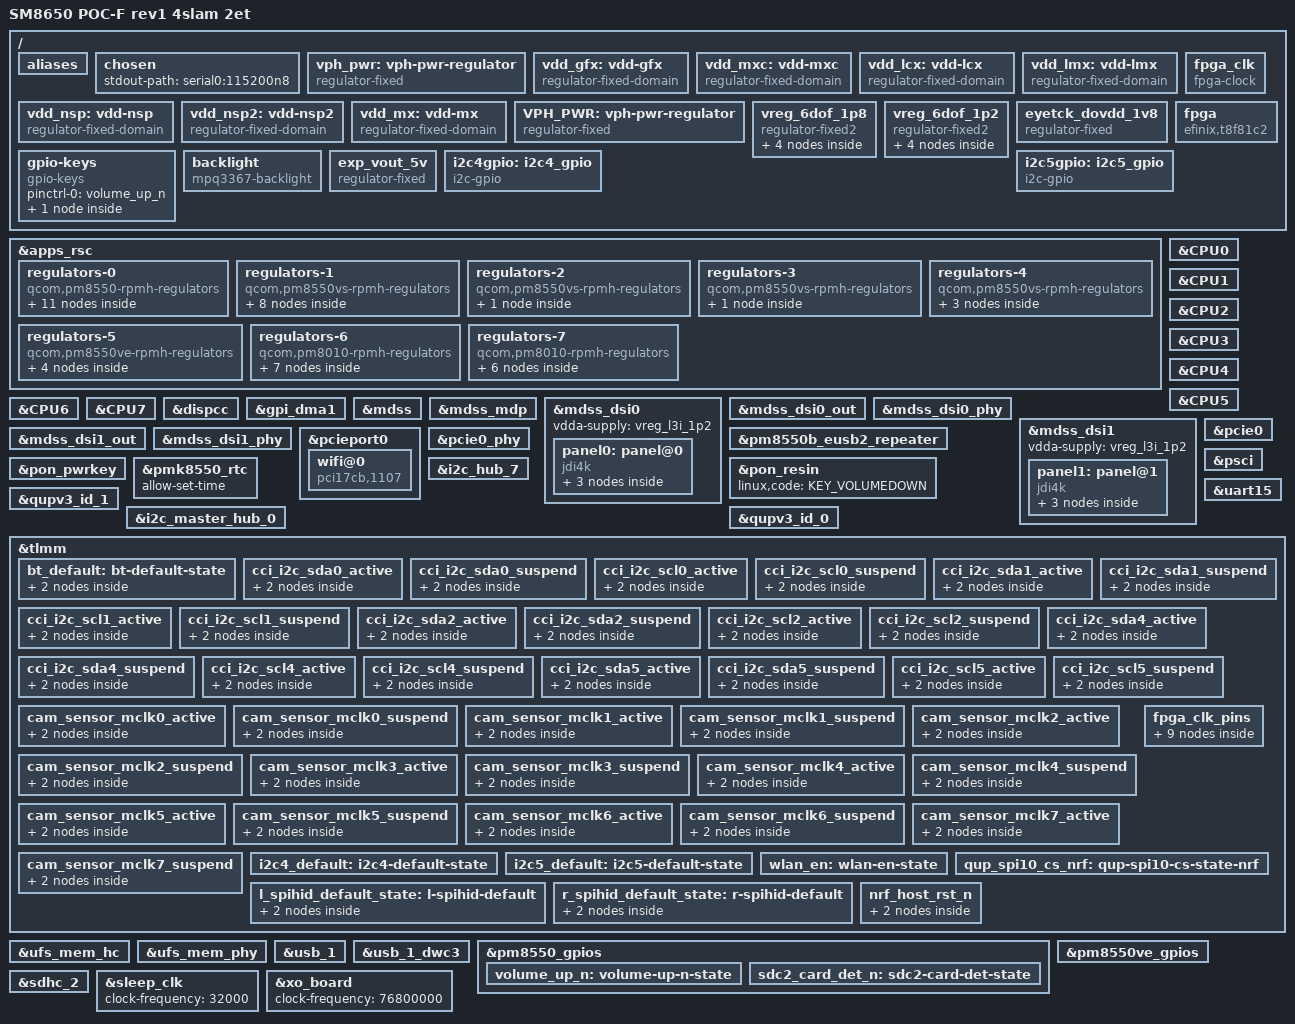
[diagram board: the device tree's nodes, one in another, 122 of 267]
/dts-v1/;

#include <dt-bindings/regulator/qcom,rpmh-regulator.h>
#include "sm8650.dtsi"

/delete-node/ &timer;

#include "pm8010.dtsi"
#include "pm8550.dtsi"
#include "pm8550b.dtsi"
#include "pm8550vs.dtsi"
#define PMK8550VE_SID 8
#include "pm8550ve.dtsi"
#include "pmk8550.dtsi"

#include <dt-bindings/regulator/qcom,rpmh-regulator.h>
#include <dt-bindings/usb/pd.h>
#include <dt-bindings/phy/phy.h>

#include <dt-bindings/input/input.h>


/ {
    model = "SM8650 POC-F rev1 4slam 2et";

	interrupt-parent = <&intc>;

	#address-cells = <2>;
	#size-cells = <2>;

	aliases {
		serial0 = &uart15;
		serial1 = &uart14;
	};

	chosen {
		stdout-path = "serial0:115200n8";
	};

	vph_pwr: vph-pwr-regulator {
		compatible = "regulator-fixed";

		regulator-name = "vph_pwr";
		regulator-min-microvolt = <3700000>;
		regulator-max-microvolt = <3700000>;

		regulator-always-on;
		regulator-boot-on;
	};

	vdd_gfx: vdd-gfx {
		compatible = "regulator-fixed-domain";
		power-domains = <&rpmhpd RPMHPD_GFX>;
		required-opps = <&rpmhpd_opp_nom>;
		regulator-name = "GFX";
		regulator-always-on;
	};

	vdd_mxc: vdd-mxc {
		compatible = "regulator-fixed-domain";
		power-domains = <&rpmhpd RPMHPD_MXC>;
		required-opps = <&rpmhpd_opp_nom>;
		regulator-name = "MXC";
		regulator-always-on;
	};

	vdd_lcx: vdd-lcx {
		compatible = "regulator-fixed-domain";
		power-domains = <&rpmhpd RPMHPD_LCX>;
		required-opps = <&rpmhpd_opp_nom>;
		regulator-name = "LCX";
		regulator-always-on;
	};

	vdd_lmx: vdd-lmx {
		compatible = "regulator-fixed-domain";
		power-domains = <&rpmhpd RPMHPD_LMX>;
		required-opps = <&rpmhpd_opp_nom>;
		regulator-name = "LMX";
		regulator-always-on;
	};

	vdd_nsp: vdd-nsp {
		compatible = "regulator-fixed-domain";
		power-domains = <&rpmhpd RPMHPD_NSP>;
		required-opps = <&rpmhpd_opp_nom>;
		regulator-name = "NSP";
		regulator-always-on;
	};

	vdd_nsp2: vdd-nsp2 {
		compatible = "regulator-fixed-domain";
		power-domains = <&rpmhpd RPMHPD_NSP2>;
		required-opps = <&rpmhpd_opp_nom>;
		regulator-name = "NSP2";
		regulator-always-on;
	};

	vdd_mx: vdd-mx {
		compatible = "regulator-fixed-domain";
		power-domains = <&rpmhpd RPMHPD_MX>;
		required-opps = <&rpmhpd_opp_nom>;
		regulator-name = "MX";
		regulator-always-on;
	};


	VPH_PWR: vph-pwr-regulator {
		compatible = "regulator-fixed";
		regulator-name = "VPH_PWR";
		regulator-min-microvolt = <3700000>;
		regulator-max-microvolt = <3700000>;

		regulator-always-on;
		regulator-boot-on;
	};

#if 0
	dummy_codec: dummy_codec {
		compatible = "linux,snd-soc-dummy";
		#sound-dai-cells = <0>;
	};

	sbu-mux {
		compatible = "gpio-sbu-mux";

		enable-gpios = <&tlmm 86 GPIO_ACTIVE_LOW>;
		select-gpios = <&tlmm 82 GPIO_ACTIVE_HIGH>;

		mode-switch;
		orientation-switch;

		port {
			sbu_mux_in: endpoint {
				remote-endpoint = <&tcpm_sbu_out>;
			};
		};

		// XXX: needs vreg_L05B_3P1, vreg_BOB2
	};
#endif

	vreg_6dof_1p8 {
		compatible = "regulator-fixed2";
		gpios = <&tlmm 36 GPIO_ACTIVE_HIGH>,
			<&tlmm 33 GPIO_ACTIVE_HIGH>;
		r-supply = <&vreg_l5m_1p8>;
		l-supply = <&vreg_l5n_1p8>;

		vreg_6dof_1p8_r: r0 {
			regulator-name = "vreg_6dof_1p8_r";
			regulator-min-microvolt = <1800000>;
			regulator-max-microvolt = <1800000>;
		};

		vreg_6dof_1p8_ur: r1 {
			regulator-name = "vreg_6dof_1p8_ur";
			regulator-min-microvolt = <1800000>;
			regulator-max-microvolt = <1800000>;
		};

		vreg_6dof_1p8_l: l0 {
			regulator-name = "vreg_6dof_1p8_l";
			regulator-min-microvolt = <1800000>;
			regulator-max-microvolt = <1800000>;
		};

		vreg_6dof_1p8_ul: l1 {
			regulator-name = "vreg_6dof_1p8_ul";
			regulator-min-microvolt = <1800000>;
			regulator-max-microvolt = <1800000>;
		};
	};

	vreg_6dof_1p2 {
		compatible = "regulator-fixed2";
		gpios = <&tlmm 37 GPIO_ACTIVE_HIGH>,
			<&tlmm 34 GPIO_ACTIVE_HIGH>;
		r-supply = <&vreg_l2m_1p2>;
		l-supply = <&vreg_l2n_1p2>;

		vreg_6dof_1p2_r: r0 {
			regulator-name = "vreg_6dof_1p2_r";
			regulator-min-microvolt = <1200000>;
			regulator-max-microvolt = <1200000>;
		};

		vreg_6dof_1p2_ur: r1 {
			regulator-name = "vreg_6dof_1p2_ur";
			regulator-min-microvolt = <1200000>;
			regulator-max-microvolt = <1200000>;
		};

		vreg_6dof_1p2_l: l0 {
			regulator-name = "vreg_6dof_1p2_l";
			regulator-min-microvolt = <1200000>;
			regulator-max-microvolt = <1200000>;
		};

		vreg_6dof_1p2_ul: l1 {
			regulator-name = "vreg_6dof_1p2_ul";
			regulator-min-microvolt = <1200000>;
			regulator-max-microvolt = <1200000>;
		};
	};

	eyetck_dovdd_1v8: eyetck_dovdd_1v8 {
		compatible = "regulator-fixed";
		regulator-name = "eyetck_dovdd_1v8";
		regulator-min-microvolt = <1800000>;
		regulator-max-microvolt = <1800000>;
		enable-active-high;
		gpio = <&tlmm 74 GPIO_ACTIVE_HIGH>;
		vin-supply = <&vreg_l5m_1p8>;
	};


	gpio-keys {
		compatible = "gpio-keys";

		pinctrl-0 = <&volume_up_n>;
		pinctrl-names = "default";

		key-volume-up {
			label = "Volume Up";
			linux,code = <KEY_VOLUMEUP>;
			gpios = <&pm8550_gpios 6 GPIO_ACTIVE_LOW>;
			debounce-interval = <15>;
			linux,can-disable;
			wakeup-source;
		};
	};

	backlight: backlight {
		compatible = "mpq3367-backlight";
		preboost-gpio = <&tlmm 41 GPIO_ACTIVE_HIGH>;
		en-gpios = <&pm8550_gpios 1 GPIO_ACTIVE_HIGH>,
			   <&pm8550_gpios 2 GPIO_ACTIVE_HIGH>;
		bias-gpios = <&pm8550_gpios 4 GPIO_ACTIVE_HIGH>,
			     <&pm8550_gpios 9 GPIO_ACTIVE_HIGH>;
		i2c-adapter = <&i2c4gpio &i2c5gpio>;
	};

	fpga_clk: fpga_clk {
		compatible = "fpga-clock";
		#clock-cells = <0>;
		clock-output-names = "fpga_clk";
		status = "okay";

		pinctrl-0 = <&fpga_clk_default>;
		pinctrl-names = "default";

		clocks = <&gcc GCC_GP3_CLK>;
		clock-frequency = <33333333>;
		clock-names = "pinclk";
	};

	fpga: fpga {
		compatible = "efinix,t8f81c2";

		clocks = <&fpga_clk>;
		clock-names = "fpga_clk";
		v1v1-supply = <&vreg_l2g_1p1>;
		pwren-gpio = <&tlmm 75 GPIO_ACTIVE_HIGH>;
	};

	exp_vout_5v: exp_vout_5v {
		compatible = "regulator-fixed";
		regulator-name = "exp_vout_5v";
		regulator-min-microvolt = <5000000>;
		regulator-max-microvolt = <5000000>;
		gpio = <&pm8550vs_g_gpios 6 GPIO_ACTIVE_HIGH>;
		enable-active-high;
		vin-supply = <&vph_pwr>;
		regulator-always-on;
	};

	i2c4gpio: i2c4_gpio {
		compatible = "i2c-gpio";
		sda-gpios = <&tlmm 48 (GPIO_ACTIVE_HIGH|GPIO_OPEN_DRAIN)>;
		scl-gpios = <&tlmm 49 (GPIO_ACTIVE_HIGH|GPIO_OPEN_DRAIN)>;

		pinctrl-0 = <&i2c4_default>;
		pinctrl-names = "default";

		#address-cells = <1>;
		#size-cells = <0>;
	};

	i2c5gpio: i2c5_gpio {
		compatible = "i2c-gpio";
		sda-gpios = <&tlmm 52 (GPIO_ACTIVE_HIGH|GPIO_OPEN_DRAIN)>;
		scl-gpios = <&tlmm 53 (GPIO_ACTIVE_HIGH|GPIO_OPEN_DRAIN)>;

		pinctrl-0 = <&i2c5_default>;
		pinctrl-names = "default";

		#address-cells = <1>;
		#size-cells = <0>;
	};
};

#if 0
&pmk8550_vadc {
	// NOTE TODO REVISIT - There is some chance to lower interrupt usage slightly if these are converted to thermal zones and qcom,adc-tm-type is set appropriately..

	// NOTE Setting qcom,adc-tm-type errors out driver and blocks all channels with obscure error. Need Thermal Zone setup to match.
	pmk8550_xo_therm {
		reg = <PMK8550_ADC5_GEN3_AMUX_THM1_XO_THERM_100K_PU>;
		label = "pmk8550_xo_therm";
		qcom,ratiometric;
		qcom,hw-settle-time = <200>;
		qcom,pre-scaling = <1 1>;
	};


	/* External PM8550 Thermistors */
	// 200 us measured on POC-F Boards as required time to reach stability.
	pcba_at_fan_exhaust {
		// Quiet Therm RT0502
		reg = <PM8550_ADC5_GEN3_AMUX_THM1_100K_PU>;
		label = "pcba_at_fan_exhaust";
		qcom,hw-settle-time = <200>;
		qcom,ratiometric;
	};

	pcba_at_40pin_connector {
		// SDM SKIN Therm RT507
		reg = <PM8550_ADC5_GEN3_AMUX_THM2_100K_PU>;
		label = "pcba_at_40pin_connector";
		qcom,hw-settle-time = <200>;
		qcom,ratiometric;
	};

	pcba_at_wifi {
		// WLAN Therm RT0503
		reg = <PM8550_ADC5_GEN3_AMUX_THM3_100K_PU>;
		label = "pcba_at_wifi";
		qcom,hw-settle-time = <200>;
		qcom,ratiometric;
	};

	pcba_at_flash {
		// ADC_1 Therm RT506
		reg = <PM8550_ADC5_GEN3_AMUX_THM4_100K_PU>;
		label = "pcba_at_flash";
		qcom,hw-settle-time = <200>;
		qcom,ratiometric;
	};

	pcba_at_nrf {
		// ADC_2 Therm RT505
		reg = <PM8550_ADC5_GEN3_AMUX_THM5_100K_PU>;
		label = "pcba_at_nrf";
		qcom,hw-settle-time = <200>;
		qcom,ratiometric;
	};


	/* External PM8550B Thermistors */
	pcba_at_heat_sink_fins {
		reg = <PM8550B_ADC5_GEN3_AMUX_THM4_USB_THERM_100K_PU>;
		label = "pcba_at_heat_sink_fins";
		qcom,hw-settle-time = <200>;
		qcom,ratiometric;
	};
};
#endif

// Different scaling for 2S
// TGOYEN - I am not fully sure how this comes about.
// It definitely doesn't match the values expected by the driver.
// I found documentation mapping 28,848 counts = 12 Amps.
// However, this is wrong since we use 4.22k for ICHG_FB which makes 60 mA steps
// So the correct mapping is 28,848 * 50 / 60 = 24,040 counts = 12 Amps
// Mapping is then 12,000,000 / 24,040
// NOTE This scaling has to be added to qcom-vadc-common.c as well
/*
&pm8550b_ichg_fb {
	qcom,pre-scaling = <24040 12000000>;
};
*/

&apps_rsc {
	/delete-property/ power-domains;

	regulators-0 {
		compatible = "qcom,pm8550-rpmh-regulators";

		vdd-bob1-supply = <&vph_pwr>;
		vdd-bob2-supply = <&vph_pwr>;
		vdd-l1-l4-l10-supply = <&vreg_s6c_1p8>;
		vdd-l2-l13-l14-supply = <&vreg_bob1>;
		vdd-l3-supply = <&vreg_s1c_1p2>;
		vdd-l5-l16-supply = <&vreg_bob1>;
		vdd-l8-l9-supply = <&vreg_bob1>;
		vdd-l12-supply = <&vreg_s6c_1p8>;
		vdd-l15-supply = <&vreg_s6c_1p8>;
		vdd-l17-supply = <&vreg_bob2>;

		qcom,pmic-id = "b";

		vreg_bob1: bob1 {
			regulator-name = "vreg_bob1";
			regulator-min-microvolt = <3296000>; // note: min is 3008000, init is 3296000
			regulator-max-microvolt = <3960000>;
			regulator-initial-mode = <RPMH_REGULATOR_MODE_HPM>;
		};

		vreg_bob2: bob2 {
			regulator-name = "vreg_bob2";
			regulator-min-microvolt = <2720000>; // note: min is 2704000, init is 2720000
			regulator-max-microvolt = <3008000>;

			regulator-initial-mode = <RPMH_REGULATOR_MODE_HPM>;

			regulator-always-on; // XXX USB HS, SBU MUX
		};

		vdd_sensor_1p8: vreg_l1b_1p8: ldo1 {
			regulator-name = "vreg_l1b_1p8";
			regulator-min-microvolt = <1800000>;
			regulator-max-microvolt = <1800000>;
			regulator-initial-mode = <RPMH_REGULATOR_MODE_HPM>;

			regulator-always-on; // XXX sensors
		};

		vdd_sensor_3p0: vreg_l2b_3p0: ldo2 {
			regulator-name = "vreg_l2b_3p0";
			regulator-min-microvolt = <3008000>;
			regulator-max-microvolt = <3008000>;
			regulator-initial-mode = <RPMH_REGULATOR_MODE_HPM>;

			regulator-always-on; // XXX sensors
		};

		vreg_l5b_3p1: ldo5 {
			regulator-name = "vreg_l5b_3p1";
			regulator-min-microvolt = <3104000>;
			regulator-max-microvolt = <3104000>;
			regulator-initial-mode = <RPMH_REGULATOR_MODE_HPM>;
			regulator-allow-set-load;
			regulator-allowed-modes = <RPMH_REGULATOR_MODE_LPM
						   RPMH_REGULATOR_MODE_HPM>;
			regulator-always-on; // XXX SBU MUX
		};

		vreg_l8b_1p8: ldo8 {
			regulator-name = "vreg_l8b_1p8";
			regulator-min-microvolt = <1800000>;
			regulator-max-microvolt = <1800000>;
			regulator-initial-mode = <RPMH_REGULATOR_MODE_HPM>;
			regulator-allow-set-load;
			regulator-allowed-modes = <RPMH_REGULATOR_MODE_LPM
						   RPMH_REGULATOR_MODE_HPM>;
		};

		vreg_l9b_2p9: ldo9 {
			regulator-name = "vreg_l9b_2p9";
			regulator-min-microvolt = <2960000>;
			regulator-max-microvolt = <2960000>;
			regulator-initial-mode = <RPMH_REGULATOR_MODE_HPM>;
			regulator-allow-set-load;
			regulator-allowed-modes = <RPMH_REGULATOR_MODE_LPM
						   RPMH_REGULATOR_MODE_HPM>;
		};

		vreg_l10b_1p8: ldo10 {
			regulator-name = "vreg_l10b_1p8";
			regulator-min-microvolt = <1800000>;
			regulator-max-microvolt = <1800000>;
			regulator-initial-mode = <RPMH_REGULATOR_MODE_HPM>;

			regulator-always-on; // XXX DMIC
		};

		vreg_l12b_1p8: ldo12 {
			regulator-name = "vreg_l12b_1p8";
			regulator-min-microvolt = <1800000>;
			regulator-max-microvolt = <1800000>;
			regulator-initial-mode = <RPMH_REGULATOR_MODE_HPM>;
			regulator-allow-set-load;
			regulator-allowed-modes = <RPMH_REGULATOR_MODE_LPM
						   RPMH_REGULATOR_MODE_HPM>;
		};

		vreg_l15b_1p8: ldo15 {
			regulator-name = "vreg_l15b_1p8";
			regulator-min-microvolt = <1800000>;
			regulator-max-microvolt = <1800000>;
			regulator-initial-mode = <RPMH_REGULATOR_MODE_HPM>;
			regulator-allow-set-load;
			regulator-allowed-modes = <RPMH_REGULATOR_MODE_LPM
						   RPMH_REGULATOR_MODE_HPM>;
			regulator-always-on; // XXX: 1.8V pull ups
		};

		vreg_l17b_2p5: ldo17 {
			regulator-name = "vreg_l17b_2p5";
			regulator-min-microvolt = <2504000>;
			regulator-max-microvolt = <2504000>;
			regulator-initial-mode = <RPMH_REGULATOR_MODE_HPM>;
			regulator-allow-set-load;
			regulator-allowed-modes = <RPMH_REGULATOR_MODE_LPM
						   RPMH_REGULATOR_MODE_HPM>;
		};
	};

	regulators-1 {
		compatible = "qcom,pm8550vs-rpmh-regulators";

		vdd-l1-supply = <&vreg_s1c_1p2>;
		vdd-l3-supply = <&vreg_s1c_1p2>;
		vdd-s1-supply = <&vph_pwr>;
		vdd-s2-supply = <&vph_pwr>;
		vdd-s3-supply = <&vph_pwr>;
		vdd-s4-supply = <&vph_pwr>;
		vdd-s5-supply = <&vph_pwr>;
		vdd-s6-supply = <&vph_pwr>;

		qcom,pmic-id = "c";

		vreg_s1c_1p2: smps1 {
			regulator-name = "vreg_s1c_1p2";
			regulator-min-microvolt = <1224000>;
			regulator-max-microvolt = <1348000>;
			// init 1256000
			regulator-initial-mode = <RPMH_REGULATOR_MODE_HPM>;

			regulator-always-on; // USB, UFS?
		};

		vreg_s2c_0p8: smps2 {
			regulator-name = "vreg_s2c_0p8";
			regulator-min-microvolt = <500000>;
			regulator-max-microvolt = <1036000>;
			// init 852000
			regulator-initial-mode = <RPMH_REGULATOR_MODE_HPM>;
		};

		vreg_s3c_0p9: smps3 {
			regulator-name = "vreg_s3c_0p9";
			regulator-min-microvolt = <904000>;
			regulator-max-microvolt = <1064000>;
			// init 976000
			regulator-initial-mode = <RPMH_REGULATOR_MODE_HPM>;
		};

		vreg_s4c_1p2: smps4 {
			regulator-name = "vreg_s4c_1p2";
			regulator-min-microvolt = <1200000>;
			regulator-max-microvolt = <1280000>;
			// init 1224000
			regulator-initial-mode = <RPMH_REGULATOR_MODE_HPM>;
		};

		vreg_s5c_0p7: smps5 {
			regulator-name = "vreg_s5c_0p7";
			regulator-min-microvolt = <300000>;
			regulator-max-microvolt = <900000>;
			// init 752000
			regulator-initial-mode = <RPMH_REGULATOR_MODE_HPM>;
		};

		vreg_s6c_1p8: smps6 {
			regulator-name = "vreg_s6c_1p8";
			regulator-min-microvolt = <1856000>;
			regulator-max-microvolt = <2000000>;
			// init 1856000
			regulator-initial-mode = <RPMH_REGULATOR_MODE_HPM>;
		};

		vreg_l1c_1p2: ldo1 {
			regulator-name = "vreg_l1c_1p2";
			regulator-min-microvolt = <1200000>; // note: min 1100000
			regulator-max-microvolt = <1200000>;
			regulator-initial-mode = <RPMH_REGULATOR_MODE_HPM>;
			regulator-allow-set-load;
			regulator-allowed-modes = <RPMH_REGULATOR_MODE_LPM
						   RPMH_REGULATOR_MODE_HPM>;
		};

		vreg_l3c_1p2: ldo3 {
			regulator-name = "vreg_l3c_1p2";
			regulator-min-microvolt = <1200000>;
			regulator-max-microvolt = <1200000>;
			regulator-initial-mode = <RPMH_REGULATOR_MODE_HPM>;
			regulator-allow-set-load;
			regulator-allowed-modes = <RPMH_REGULATOR_MODE_LPM
						   RPMH_REGULATOR_MODE_HPM>;
			regulator-always-on; // XXX: 1.2V pull ups
		};
	};

	regulators-2 {
		compatible = "qcom,pm8550vs-rpmh-regulators";
		qcom,pmic-id = "d";

		vdd-l1-supply = <&vreg_s3c_0p9>;

		vreg_l1d_0p9: ldo1 {
			regulator-name = "vreg_l1d_0p9";
			regulator-min-microvolt = <912000>; // note: min 880000
			regulator-max-microvolt = <920000>;
			regulator-initial-mode = <RPMH_REGULATOR_MODE_HPM>;
			regulator-allow-set-load;
			regulator-allowed-modes = <RPMH_REGULATOR_MODE_LPM
						   RPMH_REGULATOR_MODE_HPM>;
		};
	};

	regulators-3 {
		compatible = "qcom,pm8550vs-rpmh-regulators";
		qcom,pmic-id = "e";

		vdd-l3-supply = <&vreg_s3c_0p9>;

		vreg_l3e_0p9: ldo3 {
			regulator-name = "vreg_l3e_0p9";
			regulator-min-microvolt = <880000>;
			regulator-max-microvolt = <920000>;
			regulator-initial-mode = <RPMH_REGULATOR_MODE_HPM>;
			regulator-allow-set-load;
			regulator-allowed-modes = <RPMH_REGULATOR_MODE_LPM
						   RPMH_REGULATOR_MODE_HPM>;
		};
	};

	regulators-4 {
		compatible = "qcom,pm8550vs-rpmh-regulators";
		qcom,pmic-id = "g";

		vdd-l1-supply = <&vreg_s3c_0p9>;
		vdd-l2-supply = <&vreg_s1c_1p2>;
		vdd-l3-supply = <&vreg_s3c_0p9>;

		vreg_l1g_0p9: ldo1 {
			regulator-name = "vreg_l1g_0p9";
			regulator-min-microvolt = <912000>;
			regulator-max-microvolt = <920000>;
			regulator-initial-mode = <RPMH_REGULATOR_MODE_HPM>;
			// QLINK ?
		};

		vreg_l2g_1p1: ldo2 {
			regulator-name = "vreg_l2g_1p1";
			regulator-min-microvolt = <1104000>;
			regulator-max-microvolt = <1104000>;
			regulator-initial-mode = <RPMH_REGULATOR_MODE_HPM>;
		};

		vreg_l3g_0p91: ldo3 {
			regulator-name = "vreg_l3g_0p91";
			regulator-min-microvolt = <880000>;
			regulator-max-microvolt = <912000>;
			regulator-initial-mode = <RPMH_REGULATOR_MODE_HPM>;
		};
	};

	regulators-5 {
		compatible = "qcom,pm8550ve-rpmh-regulators";
		qcom,pmic-id = "i";

		vdd-l1-supply = <&vreg_s3c_0p9>;
		vdd-l2-supply = <&vreg_s3c_0p9>;
		vdd-l3-supply = <&vreg_s1c_1p2>;
		vdd-s4-supply = <&vph_pwr>;

		vreg_s4i_0p85: smps4 {
			regulator-name = "vreg_s4i_0p85";
			regulator-min-microvolt = <852000>;
			regulator-max-microvolt = <1004000>;
			// init 852000
			regulator-initial-mode = <RPMH_REGULATOR_MODE_HPM>;
		};

		vreg_l1i_0p88: ldo1 {
			regulator-name = "vreg_l1i_0p88";
			regulator-min-microvolt = <880000>;
			regulator-max-microvolt = <912000>;
			regulator-initial-mode = <RPMH_REGULATOR_MODE_HPM>;
			regulator-allow-set-load;
			regulator-allowed-modes = <RPMH_REGULATOR_MODE_LPM
						   RPMH_REGULATOR_MODE_HPM>;
		};

		vreg_l2i_0p88: ldo2 {
			regulator-name = "vreg_l2i_0p88";
			regulator-min-microvolt = <880000>;
			regulator-max-microvolt = <912000>;
			regulator-initial-mode = <RPMH_REGULATOR_MODE_HPM>;
			regulator-allow-set-load;
			regulator-allowed-modes = <RPMH_REGULATOR_MODE_LPM
						   RPMH_REGULATOR_MODE_HPM>;

			regulator-always-on; // CSI PHY
		};

		vreg_l3i_1p2: ldo3 {
			regulator-name = "vreg_l3i_1p2";
			regulator-min-microvolt = <1200000>;
			regulator-max-microvolt = <1200000>;
			regulator-initial-mode = <RPMH_REGULATOR_MODE_HPM>;

			regulator-always-on; // CSI PHY
		};
	};

	regulators-6 {
		compatible = "qcom,pm8010-rpmh-regulators";
		qcom,pmic-id = "m";

		vdd-l1-l2-supply = <&vreg_s1c_1p2>;
		vdd-l3-l4-supply = <&vreg_bob2>;
		vdd-l5-supply = <&vreg_s6c_1p8>;
		vdd-l6-supply = <&vreg_bob1>;
		vdd-l7-supply = <&vreg_bob1>;

		vreg_l1m_1p1: ldo1 {
			regulator-name = "vreg_l1m_1p1";
			regulator-min-microvolt = <1104000>;
			regulator-max-microvolt = <1104000>;
			regulator-initial-mode = <RPMH_REGULATOR_MODE_HPM>;
			regulator-allow-set-load;
			regulator-allowed-modes = <RPMH_REGULATOR_MODE_LPM
						   RPMH_REGULATOR_MODE_HPM>;
		};

		vreg_l2m_1p2: ldo2 {
			regulator-name = "vreg_l2m_1p2";
			regulator-min-microvolt = <1200000>;
			regulator-max-microvolt = <1200000>;
			regulator-initial-mode = <RPMH_REGULATOR_MODE_HPM>;
			regulator-allow-set-load;
			regulator-allowed-modes = <RPMH_REGULATOR_MODE_LPM
						   RPMH_REGULATOR_MODE_HPM>;
		};

		vreg_6dof_2p8_r: vreg_l3m_2p8: ldo3 {
			regulator-name = "vreg_l3m_2p8";
			regulator-min-microvolt = <2800000>;
			regulator-max-microvolt = <2800000>;
			regulator-initial-mode = <RPMH_REGULATOR_MODE_HPM>;
		};

		vreg_6dof_2p8_ur: vreg_l4m_2p8: ldo4 {
			regulator-name = "vreg_l4m_2p8";
			regulator-min-microvolt = <2800000>;
			regulator-max-microvolt = <2800000>;
			regulator-initial-mode = <RPMH_REGULATOR_MODE_HPM>;
		};

		vreg_l5m_1p8: ldo5 {
			regulator-name = "vreg_l5m_1p8";
			regulator-min-microvolt = <1800000>;
			regulator-max-microvolt = <1800000>;
			regulator-initial-mode = <RPMH_REGULATOR_MODE_HPM>;
		};

		vreg_l6m_2p8: ldo6 {
			regulator-name = "vreg_l6m_2p8";
			regulator-min-microvolt = <2800000>;
			regulator-max-microvolt = <2800000>;
			regulator-initial-mode = <RPMH_REGULATOR_MODE_HPM>;
		};

		vreg_l7m_3p3: ldo7 {
			regulator-name = "vreg_l7m_3p3";
			regulator-min-microvolt = <3304000>;
			regulator-max-microvolt = <3304000>;
			regulator-initial-mode = <RPMH_REGULATOR_MODE_HPM>;

			regulator-always-on;
		};
	};

	regulators-7 {
		compatible = "qcom,pm8010-rpmh-regulators";
		qcom,pmic-id = "n";

		vdd-l1-l2-supply = <&vreg_s1c_1p2>;
		vdd-l3-l4-supply = <&vreg_bob2>;
		vdd-l5-supply = <&vreg_s6c_1p8>;
		vdd-l6-supply = <&vreg_bob1>;

		vreg_l1n_1p1: ldo1 {
			regulator-name = "vreg_l1n_1p1";
			regulator-min-microvolt = <1104000>;
			regulator-max-microvolt = <1104000>;
			regulator-initial-mode = <RPMH_REGULATOR_MODE_HPM>;
			regulator-allow-set-load;
			regulator-allowed-modes = <RPMH_REGULATOR_MODE_LPM
						   RPMH_REGULATOR_MODE_HPM>;
		};

		vreg_l2n_1p2: ldo2 {
			regulator-name = "vreg_l2n_1p2";
			regulator-min-microvolt = <1200000>;
			regulator-max-microvolt = <1200000>;
			regulator-initial-mode = <RPMH_REGULATOR_MODE_HPM>;
			regulator-allow-set-load;
			regulator-allowed-modes = <RPMH_REGULATOR_MODE_LPM
						   RPMH_REGULATOR_MODE_HPM>;
		};

		vreg_6dof_2p8_l: vreg_l3n_2p8: ldo3 {
			regulator-name = "vreg_l3n_2p8";
			regulator-min-microvolt = <2800000>;
			regulator-max-microvolt = <2800000>;
			regulator-initial-mode = <RPMH_REGULATOR_MODE_HPM>;
		};

		vreg_6dof_2p8_ul: vreg_l4n_2p8: ldo4 {
			regulator-name = "vreg_l4n_2p8";
			regulator-min-microvolt = <2800000>;
			regulator-max-microvolt = <2800000>;
			regulator-initial-mode = <RPMH_REGULATOR_MODE_HPM>;
		};

		vreg_l5n_1p8: ldo5 {
			regulator-name = "vreg_l5n_1p8";
			regulator-min-microvolt = <1800000>;
			regulator-max-microvolt = <1800000>;
			regulator-initial-mode = <RPMH_REGULATOR_MODE_HPM>;
		};

		vreg_l6n_2p8: ldo6 {
			regulator-name = "vreg_l6n_2p8";
			regulator-min-microvolt = <2800000>;
			regulator-max-microvolt = <2800000>;
			regulator-initial-mode = <RPMH_REGULATOR_MODE_HPM>;
		};
	};
};

&CPU0 {
	/delete-property/ power-domains;
};

&CPU1 {
	/delete-property/ power-domains;
};

&CPU2 {
	/delete-property/ power-domains;
};

&CPU3 {
	/delete-property/ power-domains;
};

&CPU4 {
	/delete-property/ power-domains;
};

&CPU5 {
	/delete-property/ power-domains;
};

&CPU6 {
	/delete-property/ power-domains;
};

&CPU7 {
	/delete-property/ power-domains;
};

&dispcc {
	status = "okay";
};

&gpi_dma1 {
	status = "okay";
};

&mdss {
	status = "okay";
};

&mdss_mdp {
	status = "okay";
};

&mdss_dsi0 {
	vdda-supply = <&vreg_l3i_1p2>;
	status = "okay";

/*
	qcom,dual-dsi-mode;
	qcom,master-dsi;
*/


	panel0: panel@0 {
		reg = <0>;
		compatible = "jdi4k";
		id = <0>;

		reset-gpios =<&pm8550_gpios 3 GPIO_ACTIVE_HIGH>;
		reset2-gpios =<&pm8550_gpios 11 GPIO_ACTIVE_HIGH>;
		enp-gpios = <&tlmm 32 GPIO_ACTIVE_HIGH>;
		// XXX or tlmm 121 boost?

		wled1-supply = <&backlight>;
		vdda-supply = <&vreg_l12b_1p8>;

		//pinctrl-names = "default";
		//pinctrl-0 = <&sde_dsi_active>;

		ports {
			#address-cells = <1>;
			#size-cells = <0>;
			port@0 {
				reg = <0>;
				panel0_in: endpoint {
					remote-endpoint = <&mdss_dsi0_out>;
				};
			};

/*
			port@1 {
				reg = <1>;
				panel1_in: endpoint {
					remote-endpoint = <&mdss_dsi1_out>;
				};
			};
*/
		};
	};
};

&mdss_dsi0_out {
	remote-endpoint = <&panel0_in>;
	data-lanes = <0 1 2>;
};

&mdss_dsi0_phy {
	vdds-supply = <&vreg_l1i_0p88>;
	status = "okay";
	phy-type = <PHY_TYPE_CPHY>;
};

#if 1
&mdss_dsi1 {
	vdda-supply = <&vreg_l3i_1p2>;
	status = "okay";

#if 0
	qcom,dual-dsi-mode;

	assigned-clocks = <&dispcc DISP_CC_MDSS_BYTE1_CLK_SRC>, <&dispcc DISP_CC_MDSS_PCLK1_CLK_SRC>;
	assigned-clock-parents = <&mdss_dsi0_phy 0>, <&mdss_dsi0_phy 1>;
#endif
	panel1: panel@1 {
		reg = <0>;
		compatible = "jdi4k";
		id = <1>;

		//pinctrl-names = "default";
		//pinctrl-0 = <&sde_dsi_active>;

		ports {
			#address-cells = <1>;
			#size-cells = <0>;
			port@1 {
				reg = <1>;
				panel1_in: endpoint {
					remote-endpoint = <&mdss_dsi1_out>;
				};
			};
		};
	};
};

&mdss_dsi1_out {
	remote-endpoint = <&panel1_in>;
	data-lanes = <0 1 2>;
};

&mdss_dsi1_phy {
	vdds-supply = <&vreg_l1i_0p88>;
	status = "okay";
	phy-type = <PHY_TYPE_CPHY>;
};
#endif

#if 0
&msm_dp {
	status = "okay";
	mode-switch;
	svid = /bits/ 16 <0xff01>;

	port {
		dp_mode: endpoint@0 {
			remote-endpoint = <&dp_mode_out>;
		};
	};
};
#endif

&pcie0 {
	wake-gpios = <&tlmm 96 GPIO_ACTIVE_HIGH>;
	perst-gpios = <&tlmm 94 GPIO_ACTIVE_LOW>;

	pinctrl-names = "default";
	pinctrl-0 = <&pcie0_default_state>;

	status = "okay";
};

&pcieport0 {
	wifi@0 {
		compatible = "pci17cb,1107";
		reg = <0x10000 0x0 0x0 0x0 0x0>;

		pinctrl-names = "default";
		pinctrl-0 = <&wlan_en>;

		enable-gpios = <&tlmm 16 GPIO_ACTIVE_HIGH>;

		vddio12-supply = <&vreg_l3c_1p2>;
		vddio-supply = <&vreg_l15b_1p8>;
		vdd-supply = <&vreg_s4i_0p85>;
		vddaon-supply = <&vreg_s2c_0p8>;
		vdddig-supply = <&vreg_s3c_0p9>;
		vddrfa1-supply = <&vreg_s6c_1p8>;
		vddrfa2-supply = <&vreg_s1c_1p2>;

		clocks = <&rpmhcc RPMH_RF_CLK1>;
	};
};

&pcie0_phy {
	vdda-phy-supply = <&vreg_l1i_0p88>;
	vdda-pll-supply = <&vreg_l3i_1p2>;

	status = "okay";
};

&pm8550b_eusb2_repeater {
	vdd18-supply = <&vreg_l15b_1p8>;
	vdd3-supply = <&vreg_l5b_3p1>;
};

#if 0
&pm8550b_vbus {
	status = "okay";
};

&pm8550b_typec {
	status = "okay";

	vdd-pdphy-supply = <&vreg_l5b_3p1>;

	connector {
		power-role = "dual";
		data-role = "dual";
		try-power-role = "sink";
		source-pdos = <PDO_FIXED(5000, 1500, PDO_FIXED_DUAL_ROLE | PDO_FIXED_DATA_SWAP |
		  PDO_FIXED_USB_COMM)>;
        sink-pdos = <PDO_FIXED(5000, 3000, PDO_FIXED_DUAL_ROLE | PDO_FIXED_DATA_SWAP | PDO_FIXED_USB_COMM)>,
                    <PDO_FIXED(9000, 3000, PDO_FIXED_DUAL_ROLE | PDO_FIXED_DATA_SWAP | PDO_FIXED_USB_COMM)>;
		op-sink-microwatt = <15000000>;

		ports {
			#address-cells = <1>;
			#size-cells = <0>;

			port@0 {
				reg = <0>;

				pm8550b_role_switch_out: endpoint {
					remote-endpoint = <&usb_1_dwc3_role_switch_in>;
				};
			};

			port@1 {
				reg = <1>;

				tcpm_sbu_out: endpoint {
					remote-endpoint = <&sbu_mux_in>;
				};
			};

			port@2 {
				reg = <2>;

				dp_mode_out: endpoint {
					remote-endpoint = <&dp_mode>;
				};
			};

#if 0
			port@1 {
				reg = <1>;

				pm8550b_typec_mux_out: endpoint {
					remote-endpoint = <&usb_1_qmpphy_typec_mux_in>;
				};
			};
#endif
		};
	};

};
#endif

&pon_pwrkey {
	status = "okay";
};

&pon_resin {
	linux,code = <KEY_VOLUMEDOWN>;
	status = "okay";
};

&pmk8550_rtc {
	allow-set-time;
};

&psci {
	/delete-node/ power-domain-cpu0;
	/delete-node/ power-domain-cpu1;
	/delete-node/ power-domain-cpu2;
	/delete-node/ power-domain-cpu3;
	/delete-node/ power-domain-cpu4;
	/delete-node/ power-domain-cpu5;
	/delete-node/ power-domain-cpu6;
	/delete-node/ power-domain-cpu7;
	/delete-node/ power-domain-cluster;
};

&qupv3_id_1 {
	status = "okay";
};


#if 0
&i2c4 {
	status = "okay";

#if 0
    /* FAN_I2C */
	slg4ax46073v@8 {
		compatible = "silego,slg4ax46073v";
		reg = <0x08>;
		#address-cells = <1>;
		#size-cells = <0>;

		//vdd-fan-1-supply = <&VBATT_2S>; not modeled in dts
		fan-alert-gpios = <&tlmm 174 GPIO_ACTIVE_HIGH>;
		en-gpio = <&tlmm 138 GPIO_ACTIVE_HIGH>;
		bp-gpio = <&tlmm 139 GPIO_ACTIVE_HIGH>;

		status = "ok";
	};

	/* 3D Hall Sensor I2C */
	als31300@6c {
		compatible = "allegro,als31300";
		reg = <0x6c>;
		#address-cells = <1>;
		#size-cells = <0>;

		//vdd-hall-supply = <&VDD_SENSOR_3V0>; // Always On
		//hall-alert-gpios = <&tlmm 65 GPIO_ACTIVE_LOW>; // Not Used

		status = "ok";
	};
#endif
};

&i2c5 {
	status = "okay";
};
#endif

// Master Hub required for Hub 7 and 8
&i2c_master_hub_0 {
	status = "okay";
};

// Custom Connector I2C
&i2c_hub_7 {
	status = "okay";
};

// Prox Sensor I2C
#if 0
&i2c_hub_8 {
	status = "okay";

	light-sensor@60 {
		compatible = "vishay,vcnl4040";
		reg = <0x60>;
		proximity-near-level = <220>;
		// interrupts-extended = <&tlmm 31 IRQ_TYPE_EDGE_FALLING>;
		// driver lacks support for regulators, l8c and l11c set to always on

		vin0-supply = <&vdd_sensor_3p0>;
		vin1-supply = <&vreg_l15b_1p8>; 

		status = "okay";
	};
};
#endif

&qupv3_id_0 {
	status = "okay";
};

&qupv3_id_1 {
	status = "okay";
};

#if 0
&uart14 {
	status = "okay";

	bluetooth {
		compatible = "qcom,wcn7850-bt";

		// XXX check these
		vddio-supply = <&vreg_l15b_1p8>;
		vddaon-supply = <&vreg_s3c_0p9>;
		vdddig-supply = <&vreg_s2c_0p8>;
		vddrfa0p8-supply = <&vreg_s3c_0p9>;
		vddrfa1p2-supply = <&vreg_s1c_1p2>;
		vddrfa1p9-supply = <&vreg_s6c_1p8>;

		max-speed = <3200000>;

		enable-gpios = <&tlmm 17 GPIO_ACTIVE_HIGH>;
		swctrl-gpios = <&tlmm 18 GPIO_ACTIVE_HIGH>;

		pinctrl-0 = <&bt_default>;
		pinctrl-names = "default";

		// XXX needs to be different for each device
		local-bd-address = [ 55 44 33 22 11 00 ];
	};
};
#endif

&uart15 {
	status = "okay";
};

#if 0
&qupv3_ssc {
	status = "okay";
};

&ssc_i2c9 {
	status = "okay";
};
#endif

&tlmm {
	bt_default: bt-default-state {
		bt-en-pins {
			pins = "gpio17";
			function = "gpio";
			drive-strength = <16>;
			bias-disable;
		};

		sw-ctrl-pins {
			pins = "gpio18";
			function = "gpio";
			bias-pull-down;
		};
	};

	cci_i2c_sda0_active: cci_i2c_sda0_active {
		mux {
			/* CLK, DATA */
			pins = "gpio113";
			function = "cci_i2c_sda";
		};

		config {
			pins = "gpio113";
			bias-pull-up; /* PULL UP*/
			drive-strength = <2>; /* 2 MA */
			qcom,i2c_pull;
		};
	};

	cci_i2c_sda0_suspend: cci_i2c_sda0_suspend {
		mux {
			/* CLK, DATA */
			pins = "gpio113";
			function = "cci_i2c_sda";
		};

		config {
			pins = "gpio113";
			bias-pull-down; /* PULL DOWN */
			drive-strength = <2>; /* 2 MA */
		};
	};

	cci_i2c_scl0_active: cci_i2c_scl0_active {
		mux {
			/* CLK, DATA */
			pins = "gpio114";
			function = "cci_i2c_scl";
		};

		config {
			pins = "gpio114";
			bias-pull-up; /* PULL UP*/
			drive-strength = <2>; /* 2 MA */
			qcom,i2c_pull;
		};
	};

	cci_i2c_scl0_suspend: cci_i2c_scl0_suspend {
		mux {
			/* CLK, DATA */
			pins = "gpio114";
			function = "cci_i2c_scl";
		};

		config {
			pins = "gpio114";
			bias-pull-down; /* PULL DOWN */
			drive-strength = <2>; /* 2 MA */
		};
	};

	cci_i2c_sda1_active: cci_i2c_sda1_active {
		mux {
			/* CLK, DATA */
			pins = "gpio115";
			function = "cci_i2c_sda";
		};

		config {
			pins = "gpio115";
			bias-pull-up; /* PULL UP*/
			drive-strength = <2>; /* 2 MA */
			qcom,i2c_pull;
		};
	};

	cci_i2c_sda1_suspend: cci_i2c_sda1_suspend {
		mux {
			/* CLK, DATA */
			pins = "gpio115";
			function = "cci_i2c_sda";
		};

		config {
			pins = "gpio115";
			bias-pull-down; /* PULL DOWN */
			drive-strength = <2>; /* 2 MA */
		};
	};

	cci_i2c_scl1_active: cci_i2c_scl1_active {
		mux {
			/* CLK, DATA */
			pins = "gpio116";
			function = "cci_i2c_scl";
		};

		config {
			pins = "gpio116";
			bias-pull-up; /* PULL UP*/
			drive-strength = <2>; /* 2 MA */
			qcom,i2c_pull;
		};
	};

	cci_i2c_scl1_suspend: cci_i2c_scl1_suspend {
		mux {
			/* CLK, DATA */
			pins = "gpio116";
			function = "cci_i2c_scl";
		};

		config {
			pins = "gpio116";
			bias-pull-down; /* PULL DOWN */
			drive-strength = <2>; /* 2 MA */
		};
	};

	cci_i2c_sda2_active: cci_i2c_sda2_active {
		mux {
			/* CLK, DATA */
			pins = "gpio117";
			function = "cci_i2c_sda";
		};

		config {
			pins = "gpio117";
			bias-pull-up; /* PULL UP*/
			drive-strength = <2>; /* 2 MA */
			qcom,i2c_pull;
		};
	};

	cci_i2c_sda2_suspend: cci_i2c_sda2_suspend {
		mux {
			/* CLK, DATA */
			pins = "gpio117";
			function = "cci_i2c_sda";
		};

		config {
			pins = "gpio117";
			bias-pull-down; /* PULL DOWN */
			drive-strength = <2>; /* 2 MA */
		};
	};

	cci_i2c_scl2_active: cci_i2c_scl2_active {
		mux {
			/* CLK, DATA */
			pins = "gpio118";
			function = "cci_i2c_scl";
		};

		config {
			pins = "gpio118";
			bias-pull-up; /* PULL UP*/
			drive-strength = <2>; /* 2 MA */
			qcom,i2c_pull;
		};
	};

	cci_i2c_scl2_suspend: cci_i2c_scl2_suspend {
		mux {
			/* CLK, DATA */
			pins = "gpio118";
			function = "cci_i2c_scl";
		};

		config {
			pins = "gpio118";
			bias-pull-down; /* PULL DOWN */
			drive-strength = <2>; /* 2 MA */
		};
	};

#if 0
	cci_i2c_sda3_active: cci_i2c_sda3_active {
		mux {
			pins = "gpio12";
			function = "cci_i2c_sda";
		};

		config {
			pins = "gpio12";
			bias-pull-up; /* PULL UP*/
			drive-strength = <2>; /* 2 MA */
			qcom,i2c_pull;
		};
	};

	cci_i2c_sda3_suspend: cci_i2c_sda3_suspend {
		mux {
			pins = "gpio12";
			function = "cci_i2c_sda";
		};

		config {
			pins = "gpio12";
			bias-pull-down; /* PULL DOWN */
			drive-strength = <2>; /* 2 MA */
		};
	};


	cci_i2c_scl3_active: cci_i2c_scl3_active {
		mux {
			pins = "gpio13";
			function = "cci_i2c_scl";
		};

		config {
			pins = "gpio13";
			bias-pull-up; /* PULL UP*/
			drive-strength = <2>; /* 2 MA */
			qcom,i2c_pull;
		};
	};

	cci_i2c_scl3_suspend: cci_i2c_scl3_suspend {
		mux {
			pins = "gpio13";
			function = "cci_i2c_scl";
		};

		config {
			pins = "gpio13";
			bias-pull-down; /* PULL DOWN */
			drive-strength = <2>; /* 2 MA */
		};
	};
#endif

	cci_i2c_sda4_active: cci_i2c_sda4_active {
		mux {
			/* CLK, DATA */
			pins = "gpio112";
			function = "cci_i2c_sda";
		};

		config {
			pins = "gpio112";
			bias-pull-up; /* PULL UP*/
			drive-strength = <2>; /* 2 MA */
			qcom,i2c_pull;
		};
	};

	cci_i2c_sda4_suspend: cci_i2c_sda4_suspend {
		mux {
			/* CLK, DATA */
			pins = "gpio112";
			function = "cci_i2c_sda";
		};

		config {
			pins = "gpio112";
			bias-pull-down; /* PULL DOWN */
			drive-strength = <2>; /* 2 MA */
		};
	};

	cci_i2c_scl4_active: cci_i2c_scl4_active {
		mux {
			/* CLK, DATA */
			pins = "gpio153";
			function = "cci_i2c_scl";
		};

		config {
			pins = "gpio153";
			bias-pull-up; /* PULL UP*/
			drive-strength = <2>; /* 2 MA */
			qcom,i2c_pull;
		};
	};

	cci_i2c_scl4_suspend: cci_i2c_scl4_suspend {
		mux {
			/* CLK, DATA */
			pins = "gpio153";
			function = "cci_i2c_scl";
		};

		config {
			pins = "gpio153";
			bias-pull-down; /* PULL DOWN */
			drive-strength = <2>; /* 2 MA */
		};
	};

	cci_i2c_sda5_active: cci_i2c_sda5_active {
		mux {
			/* CLK, DATA */
			pins = "gpio119";
			function = "cci_i2c_sda";
		};

		config {
			pins = "gpio119";
			bias-pull-up; /* PULL UP*/
			drive-strength = <2>; /* 2 MA */
			qcom,i2c_pull;
		};
	};

	cci_i2c_sda5_suspend: cci_i2c_sda5_suspend {
		mux {
			/* CLK, DATA */
			pins = "gpio119";
			function = "cci_i2c_sda";
		};

		config {
			pins = "gpio119";
			bias-pull-down; /* PULL DOWN */
			drive-strength = <2>; /* 2 MA */
		};
	};

	cci_i2c_scl5_active: cci_i2c_scl5_active {
		mux {
			/* CLK, DATA */
			pins = "gpio120";
			function = "cci_i2c_scl";
		};

		config {
			pins = "gpio120";
			bias-pull-up; /* PULL UP*/
			drive-strength = <2>; /* 2 MA */
			qcom,i2c_pull;
		};
	};

	cci_i2c_scl5_suspend: cci_i2c_scl5_suspend {
		mux {
			/* CLK, DATA */
			pins = "gpio120";
			function = "cci_i2c_scl";
		};

		config {
			pins = "gpio120";
			bias-pull-down; /* PULL DOWN */
			drive-strength = <2>; /* 2 MA */
		};
	};

	cam_sensor_mclk0_active: cam_sensor_mclk0_active {
		/* MCLK0 */
		mux {
			pins = "gpio100";
			function = "cam_mclk";
		};

		config {
			pins = "gpio100";
			bias-disable; /* No PULL */
			drive-strength = <2>; /* 2 MA */
		};
	};

	cam_sensor_mclk0_suspend: cam_sensor_mclk0_suspend {
		/* MCLK0 */
		mux {
			pins = "gpio100";
			function = "cam_mclk";
		};

		config {
			pins = "gpio100";
			bias-pull-down; /* PULL DOWN */
			drive-strength = <2>; /* 2 MA */
		};
	};

	cam_sensor_mclk1_active: cam_sensor_mclk1_active {
		/* MCLK1 */
		mux {
			pins = "gpio101";
			function = "cam_mclk";
		};

		config {
			pins = "gpio101";
			bias-disable; /* No PULL */
			drive-strength = <2>; /* 2 MA */
		};
	};

	cam_sensor_mclk1_suspend: cam_sensor_mclk1_suspend {
		/* MCLK1 */
		mux {
			pins = "gpio101";
			function = "cam_mclk";
		};

		config {
			pins = "gpio101";
			bias-pull-down; /* PULL DOWN */
			drive-strength = <2>; /* 2 MA */
		};
	};

	cam_sensor_mclk2_active: cam_sensor_mclk2_active {
		/* MCLK2 */
		mux {
			pins = "gpio102";
			function = "cam_aon_mclk2";
		};

		config {
			pins = "gpio102";
			bias-disable; /* No PULL */
			drive-strength = <2>; /* 2 MA */
		};
	};

	cam_sensor_mclk2_suspend: cam_sensor_mclk2_suspend {
		/* MCLK2 */
		mux {
			pins = "gpio102";
			function = "cam_aon_mclk2";
		};

		config {
			pins = "gpio102";
			bias-pull-down; /* PULL DOWN */
			drive-strength = <2>; /* 2 MA */
		};
	};

	cam_sensor_mclk3_active: cam_sensor_mclk3_active {
		/* MCLK3 */
		mux {
			pins = "gpio103";
			function = "cam_mclk";
		};

		config {
			pins = "gpio103";
			bias-disable; /* No PULL */
			drive-strength = <2>; /* 2 MA */
		};
	};

	cam_sensor_mclk3_suspend: cam_sensor_mclk3_suspend {
		/* MCLK3 */
		mux {
			pins = "gpio103";
			function = "cam_mclk";
		};

		config {
			pins = "gpio103";
			bias-pull-down; /* PULL DOWN */
			drive-strength = <2>; /* 2 MA */
		};
	};

	cam_sensor_mclk4_active: cam_sensor_mclk4_active {
		/* MCLK4 */
		mux {
			pins = "gpio104";
			function = "cam_aon_mclk4";
		};

		config {
			pins = "gpio104";
			bias-disable; /* No PULL */
			drive-strength = <2>; /* 2 MA */
		};
	};

	cam_sensor_mclk4_suspend: cam_sensor_mclk4_suspend {
		/* MCLK4 */
		mux {
			pins = "gpio104";
			function = "cam_aon_mclk4";
		};

		config {
			pins = "gpio104";
			bias-pull-down; /* PULL DOWN */
			drive-strength = <2>; /* 2 MA */
		};
	};

	cam_sensor_mclk5_active: cam_sensor_mclk5_active {
		/* MCLK5 */
		mux {
			pins = "gpio105";
			function = "cam_mclk";
		};

		config {
			pins = "gpio105";
			bias-disable; /* No PULL */
			drive-strength = <2>; /* 2 MA */
		};
	};

	cam_sensor_mclk5_suspend: cam_sensor_mclk5_suspend {
		/* MCLK5 */
		mux {
			pins = "gpio105";
			function = "cam_mclk";
		};

		config {
			pins = "gpio105";
			bias-pull-down; /* PULL DOWN */
			drive-strength = <2>; /* 2 MA */
		};
	};

	cam_sensor_mclk6_active: cam_sensor_mclk6_active {
		/* MCLK6 */
		mux {
			pins = "gpio108";
			function = "cam_mclk";
		};

		config {
			pins = "gpio108";
			bias-disable; /* No PULL */
			drive-strength = <2>; /* 2 MA */
		};
	};

	cam_sensor_mclk6_suspend: cam_sensor_mclk6_suspend {
		/* MCLK6 */
		mux {
			pins = "gpio108";
			function = "cam_mclk";
		};

		config {
			pins = "gpio108";
			bias-pull-down; /* PULL DOWN */
			drive-strength = <2>; /* 2 MA */
		};
	};

	cam_sensor_mclk7_active: cam_sensor_mclk7_active {
		/* MCLK7 */
		mux {
			pins = "gpio106";
			function = "cam_mclk";
		};

		config {
			pins = "gpio106";
			bias-disable; /* No PULL */
			drive-strength = <2>; /* 2 MA */
		};
	};

	cam_sensor_mclk7_suspend: cam_sensor_mclk7_suspend {
		/* MCLK7 */
		mux {
			pins = "gpio106";
			function = "cam_mclk";
		};

		config {
			pins = "gpio106";
			bias-pull-down; /* PULL DOWN */
			drive-strength = <2>; /* 2 MA */
		};
	};

	i2c4_default: i2c4-default-state {
		pins = "gpio48", "gpio49";
		function = "gpio";
		drive-strength = <2>;
		bias-pull-up;
	};

	i2c5_default: i2c5-default-state {
		pins = "gpio52", "gpio53";
		function = "gpio";
		drive-strength = <2>;
		bias-pull-up;
	};

	wlan_en: wlan-en-state {
		pins = "gpio16";
		function = "gpio";
		drive-strength = <8>;
		bias-pull-down;
	};
};

&ufs_mem_hc {
	reset-gpios = <&tlmm 210 GPIO_ACTIVE_LOW>;

	vcc-supply = <&vreg_l17b_2p5>;
	vcc-max-microamp = <1300000>;
	vccq-supply = <&vreg_l1c_1p2>;
	vccq-max-microamp = <1200000>;

#if 0
	// l3c, s1c : 100 / 210000 microamp
	vccq2-supply = <&vreg_l3c_1p2>;
	vccq2-max-microamp = <100>;
#endif

	status = "okay";
};

&ufs_mem_phy {
	vdda-phy-supply = <&vreg_l1d_0p9>;
	vdda-pll-supply = <&vreg_l3i_1p2>;

	status = "okay";
};

&usb_1 {
	status = "okay";
};

&usb_1_dwc3 {
	dr_mode = "otg";
	usb-role-switch;
};

#if 0
&usb_1_dwc3_role_switch_in {
	remote-endpoint = <&pm8550b_role_switch_out>;
};

&usb_1_hsphy {
	vdd-supply = <&vreg_l1i_0p88>;
	vdda12-supply = <&vreg_l3i_1p2>;

	phys = <&pm8550b_eusb2_repeater>;

	status = "okay";
};

&usb_dp_qmpphy {
	vdda-phy-supply = <&vreg_l3i_1p2>;
	vdda-pll-supply = <&vreg_l3g_0p91>;

	orientation-switch;

	status = "okay";
};

&usb_1_qmpphy_typec_mux_in {
	remote-endpoint = <&pm8550b_typec_mux_out>;
};
#endif

#if 0
&lpass_vamacro {
	pinctrl-0 = <&dmic01_active>;
	pinctrl-names = "default";
	vdd-micb-supply = <&vreg_l10b_1p8>;
	qcom,dmic-sample-rate = <2400000>; /* or 3200000 */
};

&sound {
	status = "okay";
	codecs =
	<&left_spkr>, <&right_spkr>, <&swr0 0>,
	<&lpass_wsamacro 0>,
		 <&lpass_wsamacro 1>,
		 <&lpass_vamacro 0>, <&dummy_codec>, <&dummy_codec>;
};
#endif

&pm8550_gpios {
	volume_up_n: volume-up-n-state {
		pins = "gpio6";
		function = "normal";
		power-source = <1>;
		bias-pull-up;
		input-enable;
	};

	sdc2_card_det_n: sdc2-card-det-state {
		pins = "gpio12";
		function = "normal";
		input-enable;
		output-disable;
		bias-pull-up;
		power-source = <1>; /* 1.8 V */
	};
};

&pm8550ve_gpios {
	gpio-line-names =
		// GPIO01 - GPIO08
		"",  "",  "",  "",  "qpd_fpga_crst",  "",  "qpd_fpga_rst",  "";
};

&sdhc_2 {
	cd-gpios = <&pm8550_gpios 12 GPIO_ACTIVE_LOW>;
	pinctrl-names = "default", "sleep";
	pinctrl-0 = <&sdc2_default &sdc2_card_det_n>;
	pinctrl-1 = <&sdc2_sleep &sdc2_card_det_n>;
	vmmc-supply = <&vreg_l9b_2p9>;
	vqmmc-supply = <&vreg_l8b_1p8>; // actually level shifter
	bus-width = <4>;
	no-sdio;
	no-mmc;
	status = "okay";
};

&sleep_clk {
	clock-frequency = <32000>;
};

#if 0
&swr0 {
	status = "okay";

	/* WSA8845 */
	left_spkr: speaker@0,0 {
		compatible = "sdw20217020400";
		reg = <0 0>;
		//pinctrl-names = "default";
		//pinctrl-0 = <&spkr_1_sd_n_active>;
		powerdown-gpios = <&tlmm 186 GPIO_ACTIVE_LOW>; // LPASS 21
		#sound-dai-cells = <0>;
		sound-name-prefix = "SpkrLeft";
		vdd-1p8-supply = <&vreg_l15b_1p8>;
		vdd-io-supply = <&vreg_l3c_1p2>;
	};

	/* WSA8845 */
	right_spkr: speaker@0,1 {
		compatible = "sdw20217020400";
		reg = <0 1>;
		//pinctrl-names = "default";
		//pinctrl-0 = <&spkr_2_sd_n_active>;
		powerdown-gpios = <&tlmm 77 GPIO_ACTIVE_LOW>;
		#sound-dai-cells = <0>;
		sound-name-prefix = "SpkrRight";
		vdd-1p8-supply = <&vreg_l15b_1p8>;
		vdd-io-supply = <&vreg_l3c_1p2>;
	};
};
#endif

/*
&camss {
	status = "okay";

	ports {
		#address-cells = <1>;
		#size-cells = <0>;

		port@0 {
			reg = <0>;
			csiphy0_ep: endpoint {
				clock-lanes = <4>;
				data-lanes = <0 1>;
				remote-endpoint = <&cam_6dof_l>;
			};
		};

		port@1 {
			reg = <1>;
			csiphy1_ep: endpoint {
				clock-lanes = <4>;
				data-lanes = <0 1>;
				remote-endpoint = <&cam_6dof_r>;
			};
		};

		port@2 {
			reg = <2>;
			csiphy2_ep: endpoint {
				clock-lanes = <4>;
				data-lanes = <0>;
				remote-endpoint = <&cam_et_l>;
			};
		};

		port@4 {
			reg = <4>;
			csiphy4_ep: endpoint {
				clock-lanes = <4>;
				data-lanes = <0>;
				remote-endpoint = <&cam_et_r>;
			};
		};

		port@6 {
			reg = <6>;
			csiphy0_combo_ep: endpoint {
				clock-lanes = <3>;
				data-lanes = <2>;
				remote-endpoint = <&cam_6dof_ul>;
			};
		};

		port@7 {
			reg = <7>;
			csiphy1_combo_ep: endpoint {
				clock-lanes = <3>;
				data-lanes = <2>;
				remote-endpoint = <&cam_6dof_ur>;
			};
		};
	};
};

&cci0_i2c1 { // "CCI_1"
	cam0@60 {
		compatible = "ovti,ov6211x";
		reg = <0x60>;

		reset-gpios = <&tlmm 7 GPIO_ACTIVE_LOW>;
		pinctrl-names = "default";
		pinctrl-0 = <&cam_sensor_mclk4_active>; // <&cam_et_l_default>;

		clocks = <&camcc CAM_CC_MCLK4_CLK>;
		clock-names = "xclk";

		DOVDD-supply = <&eyetck_dovdd_1v8>;
		AVDD-supply = <&vreg_l6n_2p8>;
		DVDD-supply = <&vreg_l1n_1p1>;

		id = "eyetracking_left";

		port {
			cam_et_l: endpoint {
				clock-lanes = <4>;
				data-lanes = <0>;
				remote-endpoint = <&csiphy2_ep>;
			};
		};
	};
};

&cci1_i2c0 { // "CCI_2"
	cam0@60 {
		compatible = "ovti,ov6211x";
		reg = <0x60>;

		reset-gpios = <&tlmm 3 GPIO_ACTIVE_LOW>;
		pinctrl-names = "default";
		pinctrl-0 = <&cam_sensor_mclk2_active>; // <&cam_et_r_default>;

		clocks = <&camcc CAM_CC_MCLK2_CLK>;
		clock-names = "xclk";

		DOVDD-supply = <&eyetck_dovdd_1v8>;
		AVDD-supply = <&vreg_l6m_2p8>;
		DVDD-supply = <&vreg_l1m_1p1>;

		id = "eyetracking_right";

		port {
			cam_et_r: endpoint {
				clock-lanes = <4>;
				data-lanes = <0>;
				remote-endpoint = <&csiphy4_ep>;
			};
		};
	};
};

&cci2_i2c0 { // "CCI_4"
	cam@60 {
		compatible = "ovti,og01a1bx";
		reg = <0x60>;

		reset-gpios = <&pm8550vs_e_gpios 4 GPIO_ACTIVE_LOW>;
		strobe-gpios = <&tlmm 121 GPIO_ACTIVE_HIGH>;
		pinctrl-names = "default";
		pinctrl-0 = <&cam_sensor_mclk0_active>; // <&cam_6dof_r_default>;

		clocks = <&camcc CAM_CC_MCLK0_CLK>;
		clock-names = "xclk";

		DOVDD-supply = <&vreg_6dof_1p8_r>;
		AVDD-supply = <&vreg_6dof_2p8_r>;
		DVDD-supply = <&vreg_6dof_1p2_r>;

		id = "slam_right";

		port {
			cam_6dof_r: endpoint {
				clock-lanes = <4>;
				data-lanes = <0 1>;
				remote-endpoint = <&csiphy1_ep>;
			};
		};
	};

	cam_u@3e {
		compatible = "ovti,og01a1bx";
		reg = <0x3E>;

		reset-gpios = <&pm8550vs_c_gpios 6 GPIO_ACTIVE_LOW>;
		strobe-gpios = <&tlmm 99 GPIO_ACTIVE_HIGH>;
		pinctrl-names = "default";
		pinctrl-0 = <&cam_sensor_mclk5_active>; // <&cam_6dof_ur_default>;

		clocks = <&camcc CAM_CC_MCLK5_CLK>;
		clock-names = "xclk";

		DOVDD-supply = <&vreg_6dof_1p8_ur>;
		AVDD-supply = <&vreg_6dof_2p8_ur>;
		DVDD-supply = <&vreg_6dof_1p2_ur>;

		id = "upper_right";

		port {
			cam_6dof_ur: endpoint {
				clock-lanes = <3>;
				data-lanes = <2>;
				remote-endpoint = <&csiphy1_combo_ep>;
			};
		};
	};
};

&cci2_i2c1 { // "CCI_5"
	cam@60 {
		compatible = "ovti,og01a1bx";
		reg = <0x60>;

		reset-gpios = <&pm8550vs_e_gpios 6 GPIO_ACTIVE_LOW>;
		strobe-gpios = <&tlmm 123 GPIO_ACTIVE_HIGH>;
		pinctrl-names = "default";
		pinctrl-0 = <&cam_sensor_mclk1_active>; // <&cam_6dof_l_default>;

		clocks = <&camcc CAM_CC_MCLK1_CLK>;
		clock-names = "xclk";

		DOVDD-supply = <&vreg_6dof_1p8_l>;
		AVDD-supply = <&vreg_6dof_2p8_l>;
		DVDD-supply = <&vreg_6dof_1p2_l>;

		id = "slam_left";

		port {
			cam_6dof_l: endpoint {
				clock-lanes = <4>;
				data-lanes = <0 1>;
				remote-endpoint = <&csiphy0_ep>;
			};
		};
	};

	cam_u@3e {
		compatible = "ovti,og01a1bx";
		reg = <0x3e>;

		reset-gpios = <&pm8550vs_c_gpios 5 GPIO_ACTIVE_LOW>;
		strobe-gpios = <&tlmm 97 GPIO_ACTIVE_HIGH>;
		pinctrl-names = "default";
		pinctrl-0 = <&cam_sensor_mclk3_active>; // <&cam_6dof_ul_default>;

		clocks = <&camcc CAM_CC_MCLK3_CLK>;
		clock-names = "xclk";

		DOVDD-supply = <&vreg_6dof_1p8_ul>;
		AVDD-supply = <&vreg_6dof_2p8_ul>;
		DVDD-supply = <&vreg_6dof_1p2_ul>;

		id = "upper_left";

		port {
			cam_6dof_ul: endpoint {
				clock-lanes = <3>;
				data-lanes = <2>;
				remote-endpoint = <&csiphy0_combo_ep>;
			};
		};
	};
};
*/

// FPGA SPI and Pin setup
/*
&spi7 {
	status = "okay";
	cspi@0 {
		status = "okay";
		compatible = "linux,spidev";
		spi-max-frequency = <8000000>;
		reg = <0>;
	};
};
*/

&tlmm {
	// TODO verify reserved pins for 8650
	// qcom,gpios-reserved = <36 37 38 39>;
	gpio-line-names =
		// GPIO000 - GPIO015
		"",  "",  "",  "",  "",  "",  "",  "",  "",  "",  "",  "",  "",  "",  "",  "",
		// GPIO016 - GPIO031
		"",  "",  "",  "",  "",  "",  "",  "",  "",  "",  "",  "",  "",  "",  "",  "",
		// GPIO032 - GPIO047
		"",  "",  "",  "",  "",  "",  "",  "",  "",  "",  "",  "",  "",  "",  "",  "",
		// GPIO048 - GPIO063
		"",  "",  "",  "",  "",  "",  "",  "",  "",  "",  "qpd_fpga_qspi_cs",  "",  "",  "",  "",  "qpd_fpga_spi_cs",
		// GPIO064 - GPIO079
		"",  "",  "",  "",  "",  "",  "",  "",  "qpd_fpga_cdone",  "",  "",  "",  "",  "",  "",  "",
		// GPIO080 - GPIO095
		"",  "",  "",  "",  "",  "",  "",  "",  "",  "",  "",  "",  "",  "",  "",  "",
		// GPIO096 - GPIO111
		"",  "",  "",  "",  "",  "",  "",  "",  "",  "",  "",  "",  "",  "",  "",  "",
		// GPIO112 - GPIO127
		"",  "",  "",  "",  "",  "",  "",  "",  "",  "",  "",  "",  "",  "",  "",  "",
		// GPIO128 - GPIO143
		"",  "",  "",  "",  "",  "",  "",  "",  "",  "",  "",  "",  "",  "",  "",  "",
		// GPIO144 - GPIO159
		"",  "",  "",  "",  "",  "",  "",  "",  "",  "",  "",  "",  "",  "",  "",  "",
		// GPIO160 - GPIO175
		"",  "",  "",  "",  "",  "",  "",  "",  "",  "",  "",  "",  "",  "",  "",  "",
		// GPIO176 - GPIO180
		"",  "",  "",  "",  "", "", "", "", "", "", "", "", "", "qpd_fpga_dready";

	fpga_clk_pins {
		fpga_clk_default: fpga_clk_default {
			mux {
				pins = "gpio88";
				function = "gcc_gp3";
			};
			config {
				pins = "gpio88";
				drive-strength = <6>;
				bias-pull-none; /* pull none */
			};
		};

		fpga_clk_active: fpga_clk_active {
			mux {
				pins = "gpio88";
				function = "gcc_gp3";
			};
			config {
				pins = "gpio88";
				drive-strength = <2>; /* 2 mA */
				bias-pull-none; /* pull none */
			};
		};

		fpga_clk_sleep: fpga_clk_sleep {
			mux {
				pins = "gpio88";
				function = "gpio";
			};
			config {
				pins = "gpio88";
				drive-strength = <2>; /* 2 mA */
				bias-pull-down; /* pull down */
			};
		};
	};
};


// nRF SPI HID Config

// nRF Pins
&tlmm {
	// nRF CS
	qup_spi10_cs_nrf: qup-spi10-cs-state-nrf {
		pins = "gpio13", "gpio15";
		function = "qup2_se2";
		drive-strength = <6>;
		bias-disable;
	};

	// nRF SPI interrupt and reset pins

    // expansion 
	l_spihid_default_state: l-spihid-default {
		l_irq0 {
			pins = "gpio69";
			function = "gpio";
			bias-pull-up;
		};

		 l_reset0 {
			 pins = "gpio70";
			 function = "gpio";
			 drive-strength = <2>;
			 output-low;
			 bias-pull-down;
		 };
	};

	// host/mainboard
	r_spihid_default_state: r-spihid-default {
		r_irq0 {
			pins = "gpio66";
			function = "gpio";
			bias-pull-up;
		};

		r_reset0 {
			pins = "gpio137";
			function = "gpio";
			drive-strength = <2>;
			output-low;
			bias-pull-down;
		};
	};

	nrf_host_rst_n: nrf_host_rst_n {
		mux {
			pins = "gpio164";
			function = "gpio";
		};

		config {
			pins = "gpio164";
			power-source = <1>; /* 1.8 V */
			bias-disable = <0>;
			output-enable;
			output-low;
		};
	};
};

// nRF SPI HID
#if 0
&spi10 {
	status = "okay";

	pinctrl-0 = <&qup_spi10_data_clk>, <&qup_spi10_cs_nrf>;
	pinctrl-names = "default";

	// L, on QUP2 SE2 L3 CS
	// expansion, CS_2=gpio_15
	hid@2 {
		compatible = "hid-over-spi";
		reg = <2>;
		interrupts-extended = <&tlmm 69 IRQ_TYPE_EDGE_FALLING>;
		reset-gpios = <&tlmm 70 GPIO_ACTIVE_LOW>;
		//vdd-supply = <&vdd_3v3_reg>;
		input-report-header-address = <0x1000>;
		input-report-body-address = <0x1004>;
		output-report-address = <0x2000>;
		read-opcode = <0x0b>;
		write-opcode = <0x02>;
		hid-over-spi-flags = <0x00>;
		post-power-on-delay-ms = <1>;
		minimal-reset-delay-ms = <100>;
		pinctrl-names = "default";
		pinctrl-0 = <&l_spihid_default_state>;
	};

	// R, on QUP2 SE2 L6 CS
	// mainboard, CS_1=gpio_13
	hid@1 {
		compatible = "hid-over-spi";
		reg = <1>;
		interrupts-extended = <&tlmm 66 IRQ_TYPE_EDGE_FALLING>;
		reset-gpios = <&tlmm 137 GPIO_ACTIVE_LOW>;
		//vdd-supply = <&vdd_3v3_reg>;
		input-report-header-address = <0x1000>;
		input-report-body-address = <0x1004>;
		output-report-address = <0x2000>;
		read-opcode = <0x0b>;
		write-opcode = <0x02>;
		hid-over-spi-flags = <0x00>;
		post-power-on-delay-ms = <1>;
		minimal-reset-delay-ms = <100>;
		pinctrl-names = "default";
		pinctrl-0 = <&r_spihid_default_state>;
		//pinctrl-0 = <&r_spihid_default_state>, <&nrf_host_rst_n>;
		//pinctrl-assert-gpios = < &tlmm 164 GPIO_ACTIVE_LOW >;
    };
};
#endif

&xo_board {
	clock-frequency = <76800000>;
};
